# tviic2d6m register map
Vendor: Infineon Technologies; Series: TVIIC2D6M; File version: 1.0
CPU: CM7 r0p1, little endian, MPU, FPU, double-precision FPU, I-cache, D-cache, VTOR, ITCM, DTCM, 3 interrupt priority bits, 16 interrupts
Registers are 32-bit, read-write, reset 0x0 unless marked. A register's access mark holds for its fields unless they carry their own. Offsets are from the block's base; [hi:lo] are bit positions; lines under a group give offsets from that group; {n}, {i} and the like mark numbered series.

## SG0 — SG
Base 0x40820000
{0x8000+0x100*i} SG_STRUCT[{i}] (i=0..4) group — Sound generator structure
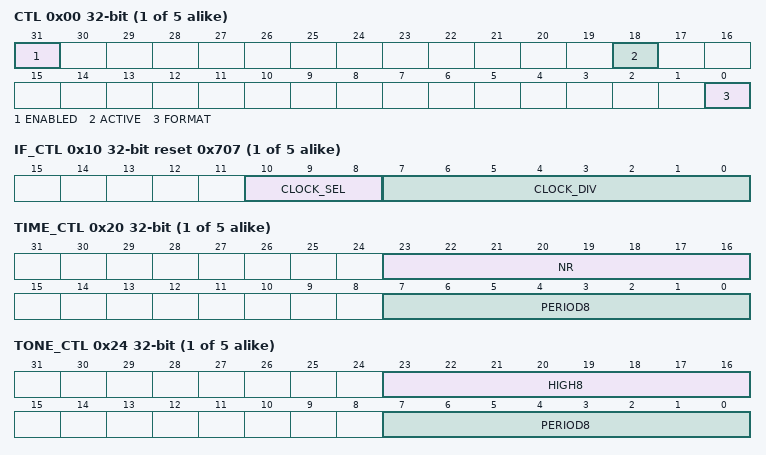
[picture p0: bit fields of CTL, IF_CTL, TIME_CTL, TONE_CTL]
  0x00 CTL — Source control
    [31] ENABLED — Source enable: '0': Disabled. All non-retained MMIO registers (e.g. TIME_CTL, ..., INTR_TX register) have their fields reset to their default value. '1': Enabled.
    [18] ACTIVE — Activate functionality: '0': Transmitter off. The UNDERFLOW interrupt cause will not be activated (provided SW never set this bit). '1': Transmitter on. The UNDERFLOW interrupt may be activated (when an underflow event occurs). Note: This functionality is intended for startup purposes. Typically, SW sets ACTIVE to '1' after the segment structure and the buffered segment structure are written with valid information. Note: SW clearing ACTIVE to '0' (after setting ACTIVE to '1') is not intended usage model and it has no effect on HW functionality.
    [0] FORMAT — Output format: '0': Separate. The 'sg_ampl_out' (amplitude signal) and 'sg_tone_out' (tone signal) output signals are driven seperately. '1': Combined. The 'sg_tone_out' output signal is the logical AND of the amplitude signal and tone signal.
      0=SEPARATE (N/A); 1=COMBINED (N/A)
  0x10 IF_CTL reset 0x707 — Interface control
    [10:8] CLOCK_SEL — Interface clock clk_if selection: '0': SRSS clock clk_if_srss[0]. '1': SRSS clock clk_if_srss[1]. '2': SRSS clock clk_if_srss[2]. '3': SRSS clock clk_if_srss[3]. '4': Master interface clock 'sg_mck_in'. '5'-'7': undefined. Note: the application is always required to program this field to a value different from the default.
      {v}=SEL_SRSS_CLOCK{v} (N/A) (v=0..3); 4=SEL_SG_MCK_IN (N/A)
    [7:0] CLOCK_DIV — Interface clock divider (legal range [0, 255]). The PWM interface clock clk_pwm is defined as clk_if / (CLOCK_DIV + 1). '0': clk_pwm frequency is clk_if frequency (1 clk_pwm cycle consists of 1 clk_if cycles). '1': clk_pwm frequency is 1/2 clk_if frequency (1 clk_pwm cycle consists of 2 clk_if cycles). '2': clk_pwm frequency is 1/3 clk_if frequency. ... '255': clk_pwm frequency is 1/256 clk_if frequency.
  0x20 TIME_CTL — Time control
    [23:16] NR — Segment in time periods: a single segment is (NR+1) timer periods. HW activates the 'completion' event on completion of a segment descriptor (in registers STEP_CTL, AMPL_CTL, TONE_CTL and TIME_CTL).
    [7:0] PERIOD8 — Time period in tone periods: a single time period is (PERIOD + 1) tone periods. A tone period is considered a time cycle. HW updates the AMPL_CTL.HIGH value after completion of a time period.
  0x24 TONE_CTL — Tone control
    [23:16] HIGH8 — Specifies the high/'1' time of the generated (right-aligned) tone PWM signal: the 'sg_tone_out' signal is '1' for HIGH+1 PWM periods. Clipping is applied if HIGH exceeds its legal range of [0, PERIOD] (the high/'1' time of the period is up to 50 percent) Note: To generate a 50/50 percent duty cycle, HIGH should equal PERIOD.
    [7:0] PERIOD8 — Tone period in amplitude periods: a single tone period is 2 * (PERIOD + 1) amplitude periods. A ampolitude period is considered a tone cycle.
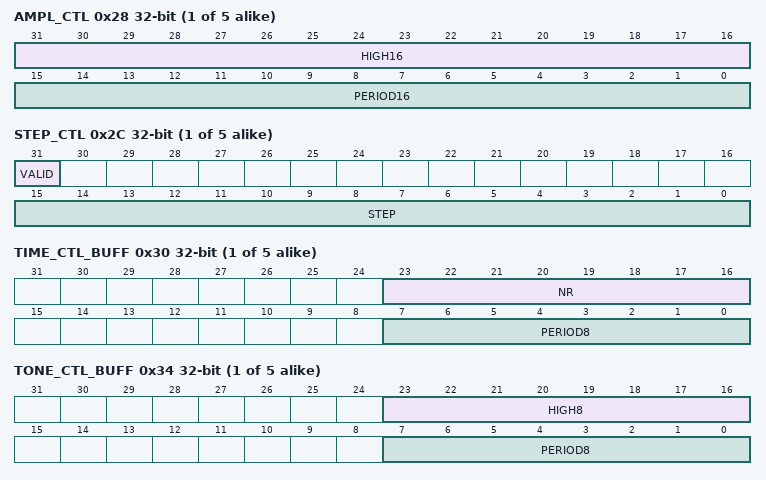
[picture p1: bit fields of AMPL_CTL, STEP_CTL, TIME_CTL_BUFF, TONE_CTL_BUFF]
  0x28 AMPL_CTL — Amplitude control
    [31:16] HIGH16 — Specifies the high/'1' of the generated (left-aligned) amplitude PWM waveform: the 'sg_ampl_out' output signal is '1' for HIGH+1 interface clock 'clk_pwm' cycles. The legal range is [0, PERIOD].
    [15:0] PERIOD16 — Amplitude period in interface clock 'clk_pwm' cycles: a single amplitude period is PERIOD+1 'clk_pwm' cycles.
  0x2C STEP_CTL — Step control
    [31] VALID — Specifies validity/availability of the segment structure (TIME_CTL, NOTE_CTL, AMPL_CTL and STEP_CTL): '0': Invalid. '1': Valid.
    [15:0] STEP — Specifies the amplitude step size of the generated PWM waveform. The value is a two-complements signed number with a legal range of [-32768, 32767]. The value is added to HIGH after completion of a time period. Clipping is applied if HIGH exceeds its legal range of [0, AMPL_CTL.PERIOD].
  0x30 TIME_CTL_BUFF — Buffered time control
    [23:16] NR — See TIME_CTL.
    [7:0] PERIOD8 — See TIME_CTL.
  0x34 TONE_CTL_BUFF — Buffered tone control
    [23:16] HIGH8 — See TONE_CTL.
    [7:0] PERIOD8 — See TONE_CTL.
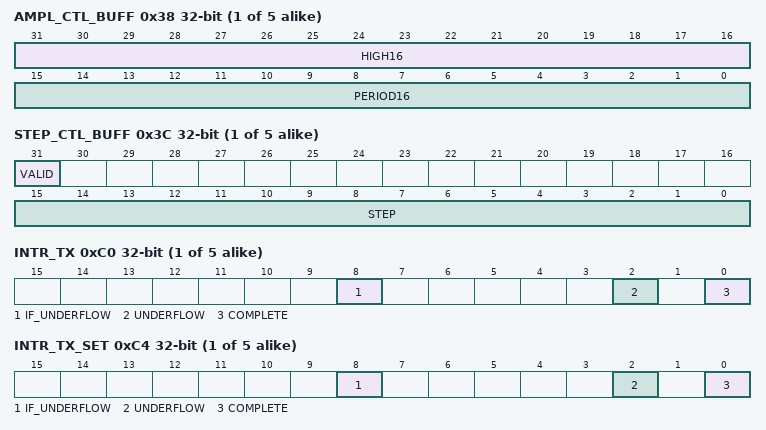
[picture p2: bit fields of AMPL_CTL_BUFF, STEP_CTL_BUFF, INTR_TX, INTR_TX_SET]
  0x38 AMPL_CTL_BUFF — Buffered amplitude control
    [31:16] HIGH16 — See AMPL_CTL.
    [15:0] PERIOD16 — See AMPL_CTL.
  0x3C STEP_CTL_BUFF — Buffered step control
    [31] VALID — Specifies validity of the buffered segment structure: '0': Invalid. '1': Valid. HW clears this field to '0' on a completion event. Typically, SW sets this field to '1' when a new buffered segment structure is written. An underflow event is generated when STEP_CTL_BUFF.VALID is '0' on a completion event.
    [15:0] STEP — See STEP_CTL.
  0xC0 INTR_TX — Interrupt
    [8] IF_UNDERFLOW write-1-clears — HW sets this field to '1', when (amplitude, tone) sample pairs are not generated in time for the interface logic (interface underflow). This may be an indication that the IP system frequency is too low wrt. the interface frequency (a SW configuration error). The interface underflow is a non-recoverable error and requires SW disabling of the channel (a SW write to INTR_TX.IF_UNDERFLOW does not resolve the interface underflow). The interface drives the 'sg_ampl_out' and 'sg_tone_out' output signals to '0'. Note: This functionality is intended for debug purposes.
    [2] UNDERFLOW write-1-clears — HW sets this field to '1', on a completion event when STEP_CTL_BUFF.VALID is '0'; i.e. a new segment structure is NOT valid/available.
    [0] COMPLETE write-1-clears — HW sets this field to '1', on a completion event (completion of a segment descriptor).
  0xC4 INTR_TX_SET — Interrupt set
    [8] IF_UNDERFLOW write-1-sets — Write this field with '1' to set corresponding INTR_TX field (a write of '0' has no effect).
    [2] UNDERFLOW write-1-sets — Write this field with '1' to set corresponding INTR_TX field (a write of '0' has no effect).
    [0] COMPLETE write-1-sets — Write this field with '1' to set corresponding INTR_TX field (a write of '0' has no effect).
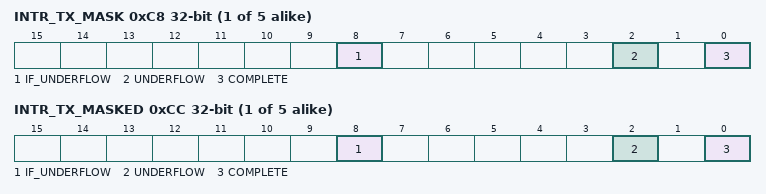
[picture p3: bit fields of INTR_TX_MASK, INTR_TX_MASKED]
  0xC8 INTR_TX_MASK — Interrupt mask
    [8] IF_UNDERFLOW — Mask for corresponding field in INTR_TX register.
    [2] UNDERFLOW — Mask for corresponding field in INTR_TX register.
    [0] COMPLETE — Mask for corresponding field in INTR_TX register.
  0xCC INTR_TX_MASKED ro — Interrupt masked
    [8] IF_UNDERFLOW — Logical AND of corresponding INTR_TX and INTR_TX_MASK fields.
    [2] UNDERFLOW — Logical AND of corresponding INTR_TX and INTR_TX_MASK fields.
    [0] COMPLETE — Logical AND of corresponding INTR_TX and INTR_TX_MASK fields.
